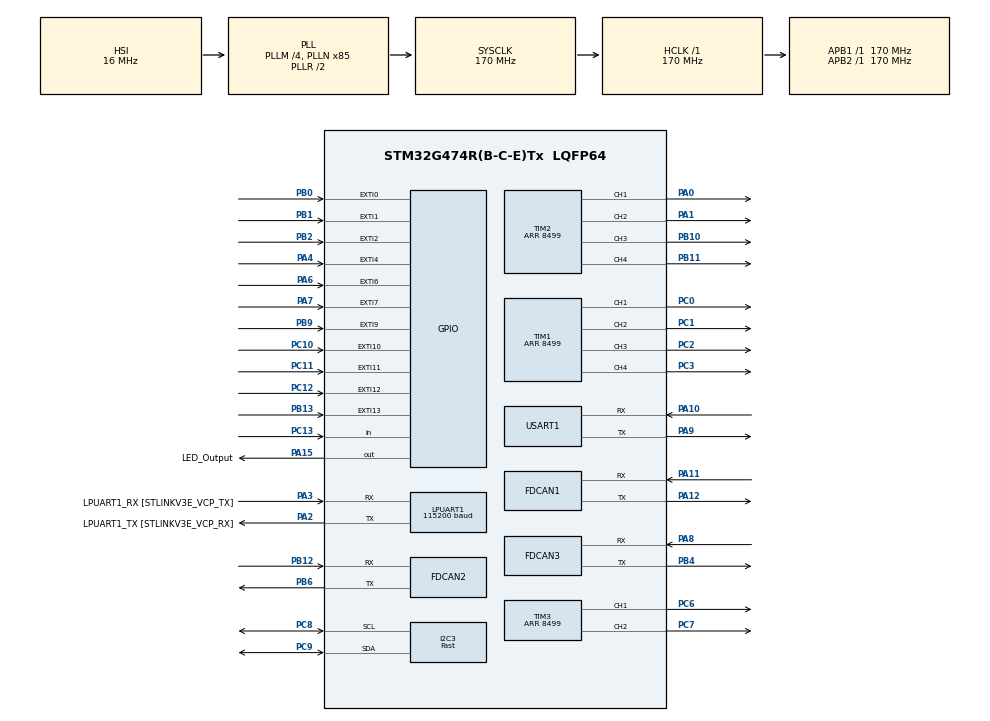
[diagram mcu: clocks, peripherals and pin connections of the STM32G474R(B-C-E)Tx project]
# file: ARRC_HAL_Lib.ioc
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FDCAN1.CalculateBaudRateNominal=1000000
FDCAN1.CalculateTimeBitNominal=1000
FDCAN1.CalculateTimeQuantumNominal=100.0
FDCAN1.NominalPrescaler=17
FDCAN1.NominalTimeSeg1=8
FDCAN2.CalculateBaudRateNominal=1000000
FDCAN2.CalculateTimeBitNominal=1000
FDCAN2.CalculateTimeQuantumNominal=100.0
FDCAN2.NominalPrescaler=17
FDCAN2.NominalTimeSeg1=8
FDCAN3.CalculateBaudRateNominal=1000000
FDCAN3.CalculateTimeBitNominal=1000
FDCAN3.CalculateTimeQuantumNominal=100.0
FDCAN3.NominalPrescaler=17
FDCAN3.NominalTimeSeg1=8
I2C3.I2C_Fall_Time=0
I2C3.I2C_Rise_Time=0
I2C3.I2C_Speed_Mode=I2C_Fast
I2C3.Speed=400
I2C3.Timing=0x10802D9B
LPUART1.BaudRate=115200
Mcu.Family=STM32G4
Mcu.Name=STM32G474R(B-C-E)Tx
Mcu.Package=LQFP64
NVIC.EXTI0_IRQn=true\:0\:0\:false\:false\:true\:true\:true\:true
NVIC.EXTI15_10_IRQn=true\:0\:0\:false\:false\:true\:true\:true\:true
NVIC.EXTI1_IRQn=true\:0\:0\:false\:false\:true\:true\:true\:true
NVIC.EXTI2_IRQn=true\:0\:0\:false\:false\:true\:true\:true\:true
NVIC.EXTI4_IRQn=true\:0\:0\:false\:false\:true\:true\:true\:true
NVIC.EXTI9_5_IRQn=true\:0\:0\:false\:false\:true\:true\:true\:true
NVIC.FDCAN1_IT0_IRQn=true\:0\:0\:false\:false\:true\:true\:true\:true
NVIC.FDCAN2_IT0_IRQn=true\:0\:0\:false\:false\:true\:true\:true\:true
NVIC.FDCAN3_IT0_IRQn=true\:0\:0\:false\:false\:true\:true\:true\:true
NVIC.I2C3_EV_IRQn=true\:0\:0\:false\:false\:true\:true\:true\:true
NVIC.PriorityGroup=NVIC_PRIORITYGROUP_4
NVIC.TIM7_DAC_IRQn=true\:0\:0\:false\:false\:true\:true\:true\:true
PA0.Signal=S_TIM2_CH1
PA1.Signal=S_TIM2_CH2
PA10.Mode=Asynchronous
PA10.Signal=USART1_RX
PA11.Mode=FDCAN_Activate
PA11.Signal=FDCAN1_RX
PA12.Mode=FDCAN_Activate
PA12.Signal=FDCAN1_TX
PA13.GPIO_Label=T_SWDIO
PA13.Signal=SYS_JTMS-SWDIO
PA14.GPIO_Label=T_SWCLK
PA14.Signal=SYS_JTCK-SWCLK
PA15.GPIO_Label=LED_Output
PA15.Signal=GPIO_Output
PA2.GPIO_Label=LPUART1_TX [STLINKV3E_VCP_RX]
PA2.Mode=Asynchronous
PA2.Signal=LPUART1_TX
PA3.GPIO_Label=LPUART1_RX [STLINKV3E_VCP_TX]
PA3.Mode=Asynchronous
PA3.Signal=LPUART1_RX
PA4.GPIO_ModeDefaultEXTI=GPIO_MODE_IT_RISING_FALLING
PA4.Signal=GPXTI4
PA6.GPIO_ModeDefaultEXTI=GPIO_MODE_IT_RISING_FALLING
PA6.Signal=GPXTI6
PA7.GPIO_ModeDefaultEXTI=GPIO_MODE_IT_RISING_FALLING
PA7.Signal=GPXTI7
PA8.Mode=FDCAN_Activate
PA8.Signal=FDCAN3_RX
PA9.Mode=Asynchronous
PA9.Signal=USART1_TX
PB0.GPIO_ModeDefaultEXTI=GPIO_MODE_IT_RISING_FALLING
PB0.Signal=GPXTI0
PB1.GPIO_ModeDefaultEXTI=GPIO_MODE_IT_RISING_FALLING
PB1.Signal=GPXTI1
PB10.Signal=S_TIM2_CH3
PB11.Signal=S_TIM2_CH4
PB12.Mode=FDCAN_Activate
PB12.Signal=FDCAN2_RX
PB13.GPIO_ModeDefaultEXTI=GPIO_MODE_IT_RISING_FALLING
PB13.Signal=GPXTI13
PB2.GPIO_ModeDefaultEXTI=GPIO_MODE_IT_RISING_FALLING
PB2.Signal=GPXTI2
PB3.GPIO_Label=T_SWO
PB3.Signal=SYS_JTDO-SWO
PB4.Mode=FDCAN_Activate
PB4.Signal=FDCAN3_TX
PB6.Mode=FDCAN_Activate
PB6.Signal=FDCAN2_TX
PB9.GPIO_ModeDefaultEXTI=GPIO_MODE_IT_RISING_FALLING
PB9.Signal=GPXTI9
PC0.Signal=S_TIM1_CH1
PC1.Signal=S_TIM1_CH2
PC10.GPIO_ModeDefaultEXTI=GPIO_MODE_IT_RISING_FALLING
PC10.Signal=GPXTI10
PC11.GPIO_ModeDefaultEXTI=GPIO_MODE_IT_RISING_FALLING
PC11.Signal=GPXTI11
PC12.GPIO_ModeDefaultEXTI=GPIO_MODE_IT_RISING_FALLING
PC12.Signal=GPXTI12
PC13.Signal=GPIO_Input
PC14-OSC32_IN.GPIO_Label=RCC_OSC32_IN
PC14-OSC32_IN.Signal=RCC_OSC32_IN
PC15-OSC32_OUT.GPIO_Label=RCC_OSC32_OUT
PC15-OSC32_OUT.Signal=RCC_OSC32_OUT
PC2.Signal=S_TIM1_CH3
PC3.Signal=S_TIM1_CH4
PC6.Signal=S_TIM3_CH1
PC7.Signal=S_TIM3_CH2
PC8.GPIO_Pu=GPIO_PULLUP
PC8.Mode=I2C
PC8.Signal=I2C3_SCL
PC9.GPIO_Pu=GPIO_PULLUP
PC9.Mode=I2C
PC9.Signal=I2C3_SDA
PF0-OSC_IN.GPIO_Label=RCC_OSC_IN
PF0-OSC_IN.Signal=RCC_OSC_IN
PF1-OSC_OUT.GPIO_Label=RCC_OSC_OUT
PF1-OSC_OUT.Signal=RCC_OSC_OUT
ProjectManager.HeapSize=0x200
ProjectManager.StackSize=0x400
ProjectManager.TargetToolchain=CMake
RCC.ADC12Freq_Value=170000000
RCC.ADC345Freq_Value=170000000
RCC.AHBFreq_Value=170000000
RCC.APB1Freq_Value=170000000
RCC.APB1TimFreq_Value=170000000
RCC.APB2Freq_Value=170000000
RCC.APB2TimFreq_Value=170000000
RCC.CortexFreq_Value=170000000
RCC.EXTERNAL_CLOCK_VALUE=12288000
RCC.HCLKFreq_Value=170000000
RCC.HSE_VALUE=24000000
RCC.HSI48_VALUE=48000000
RCC.HSI_VALUE=16000000
RCC.LSE_VALUE=32768
RCC.PLLM=RCC_PLLM_DIV4
RCC.PLLN=85
RCC.RTCClockSelection=RCC_RTCCLKSOURCE_LSE
RCC.SYSCLKFreq_VALUE=170000000
RCC.SYSCLKSource=RCC_SYSCLKSOURCE_PLLCLK
RCC.USBFreq_Value=170000000
RCC.VCOOutputFreq_Value=340000000
SH.S_TIM1_CH1.0=TIM1_CH1,PWM Generation1 CH1
SH.S_TIM1_CH2.0=TIM1_CH2,PWM Generation2 CH2
SH.S_TIM1_CH3.0=TIM1_CH3,PWM Generation3 CH3
SH.S_TIM1_CH4.0=TIM1_CH4,PWM Generation4 CH4
SH.S_TIM2_CH1.0=TIM2_CH1,PWM Generation1 CH1
SH.S_TIM2_CH2.0=TIM2_CH2,PWM Generation2 CH2
SH.S_TIM2_CH3.0=TIM2_CH3,PWM Generation3 CH3
SH.S_TIM2_CH4.0=TIM2_CH4,PWM Generation4 CH4
SH.S_TIM3_CH1.0=TIM3_CH1,PWM Generation1 CH1
SH.S_TIM3_CH2.0=TIM3_CH2,PWM Generation2 CH2
TIM1.AutoReloadPreload=TIM_AUTORELOAD_PRELOAD_ENABLE
TIM1.Channel-PWM\ Generation1\ CH1=TIM_CHANNEL_1
TIM1.Channel-PWM\ Generation2\ CH2=TIM_CHANNEL_2
TIM1.Channel-PWM\ Generation3\ CH3=TIM_CHANNEL_3
TIM1.Channel-PWM\ Generation4\ CH4=TIM_CHANNEL_4
TIM1.PeriodNoDither=8499
TIM2.AutoReloadPreload=TIM_AUTORELOAD_PRELOAD_ENABLE
TIM2.Channel-PWM\ Generation1\ CH1=TIM_CHANNEL_1
TIM2.Channel-PWM\ Generation2\ CH2=TIM_CHANNEL_2
TIM2.Channel-PWM\ Generation3\ CH3=TIM_CHANNEL_3
TIM2.Channel-PWM\ Generation4\ CH4=TIM_CHANNEL_4
TIM2.PeriodNoDither=8499
TIM3.AutoReloadPreload=TIM_AUTORELOAD_PRELOAD_ENABLE
TIM3.Channel-PWM\ Generation1\ CH1=TIM_CHANNEL_1
TIM3.Channel-PWM\ Generation2\ CH2=TIM_CHANNEL_2
TIM3.PeriodNoDither=8499
TIM7.PeriodNoDither=1700-1
TIM7.Prescaler=100-1
USART1.VirtualMode-Asynchronous=VM_ASYNC
VP_SYS_VS_DBSignals.Mode=DisableDeadBatterySignals
VP_TIM1_VS_ClockSourceINT.Mode=Internal
VP_TIM2_VS_ClockSourceINT.Mode=Internal
VP_TIM3_VS_ClockSourceINT.Mode=Internal
VP_TIM7_VS_ClockSourceINT.Mode=Enable_Timer
board=NUCLEO-G474RE

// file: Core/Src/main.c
/* USER CODE BEGIN Header */
/**
  ******************************************************************************
  * @file           : main.c
  * @brief          : Main program body
  ******************************************************************************
  * @attention
  *
  * Copyright (c) 2025 STMicroelectronics.
  * All rights reserved.
  *
  * This software is licensed under terms that can be found in the LICENSE file
  * in the root directory of this software component.
  * If no LICENSE file comes with this software, it is provided AS-IS.
  *
  ******************************************************************************
  */
/* USER CODE END Header */
#include "main.h"
#include "fdcan.h"
#include "i2c.h"
#include "usart.h"
#include "tim.h"
#include "gpio.h"

/* USER CODE BEGIN Includes */
#include "stdio.h"
/* USER CODE END Includes */

void SystemClock_Config(void);
/* USER CODE BEGIN PFP */
#ifdef HAL_UART_MODULE_ENABLED
int __io_putchar(int ch)
{
  HAL_UART_Transmit(&hlpuart1, (uint8_t *)&ch, 1, 100);

  return ch;
}
#endif // HAL_UART_MODULE_ENABLED
/* USER CODE END PFP */

int main(void)
{

  /* USER CODE BEGIN 1 */
   setbuf(stdout, NULL);
  /* USER CODE END 1 */

  /* MCU Configuration--------------------------------------------------------*/

  /* Reset of all peripherals, Initializes the Flash interface and the Systick. */
  HAL_Init();

  /* Configure the system clock */
  SystemClock_Config();

  /* Initialize all configured peripherals */
  MX_GPIO_Init();
  MX_FDCAN1_Init();
  MX_FDCAN2_Init();
  MX_FDCAN3_Init();
  MX_I2C3_Init();
  MX_LPUART1_UART_Init();
  MX_TIM2_Init();
  MX_USART1_UART_Init();
  MX_TIM1_Init();
  MX_TIM3_Init();
  MX_TIM7_Init();
  /* USER CODE BEGIN 2 */
  cpp_main();
  /* USER CODE END 2 */

  /* Infinite loop */
  while (1)
  {

  }
}

void SystemClock_Config(void)
{
  RCC_OscInitTypeDef RCC_OscInitStruct = {0};
  RCC_ClkInitTypeDef RCC_ClkInitStruct = {0};

  /** Configure the main internal regulator output voltage
  */
  HAL_PWREx_ControlVoltageScaling(PWR_REGULATOR_VOLTAGE_SCALE1_BOOST);

  /** Initializes the RCC Oscillators according to the specified parameters
  * in the RCC_OscInitTypeDef structure.
  */
  RCC_OscInitStruct.OscillatorType = RCC_OSCILLATORTYPE_HSI;
  RCC_OscInitStruct.HSIState = RCC_HSI_ON;
  RCC_OscInitStruct.HSICalibrationValue = RCC_HSICALIBRATION_DEFAULT;
  RCC_OscInitStruct.PLL.PLLState = RCC_PLL_ON;
  RCC_OscInitStruct.PLL.PLLSource = RCC_PLLSOURCE_HSI;
  RCC_OscInitStruct.PLL.PLLM = RCC_PLLM_DIV4;
  RCC_OscInitStruct.PLL.PLLN = 85;
  RCC_OscInitStruct.PLL.PLLP = RCC_PLLP_DIV2;
  RCC_OscInitStruct.PLL.PLLQ = RCC_PLLQ_DIV2;
  RCC_OscInitStruct.PLL.PLLR = RCC_PLLR_DIV2;
  if (HAL_RCC_OscConfig(&RCC_OscInitStruct) != HAL_OK)
  {
    Error_Handler();
  }

  /** Initializes the CPU, AHB and APB buses clocks
  */
  RCC_ClkInitStruct.ClockType = RCC_CLOCKTYPE_HCLK|RCC_CLOCKTYPE_SYSCLK
                              |RCC_CLOCKTYPE_PCLK1|RCC_CLOCKTYPE_PCLK2;
  RCC_ClkInitStruct.SYSCLKSource = RCC_SYSCLKSOURCE_PLLCLK;
  RCC_ClkInitStruct.AHBCLKDivider = RCC_SYSCLK_DIV1;
  RCC_ClkInitStruct.APB1CLKDivider = RCC_HCLK_DIV1;
  RCC_ClkInitStruct.APB2CLKDivider = RCC_HCLK_DIV1;

  if (HAL_RCC_ClockConfig(&RCC_ClkInitStruct, FLASH_LATENCY_4) != HAL_OK)
  {
    Error_Handler();
  }
}

void Error_Handler(void)
{
  /* USER CODE BEGIN Error_Handler_Debug */
  /* User can add his own implementation to report the HAL error return state */
  __disable_irq();
  printf("ERROR\n");
  while (1)
  {
  }
  /* USER CODE END Error_Handler_Debug */
}
